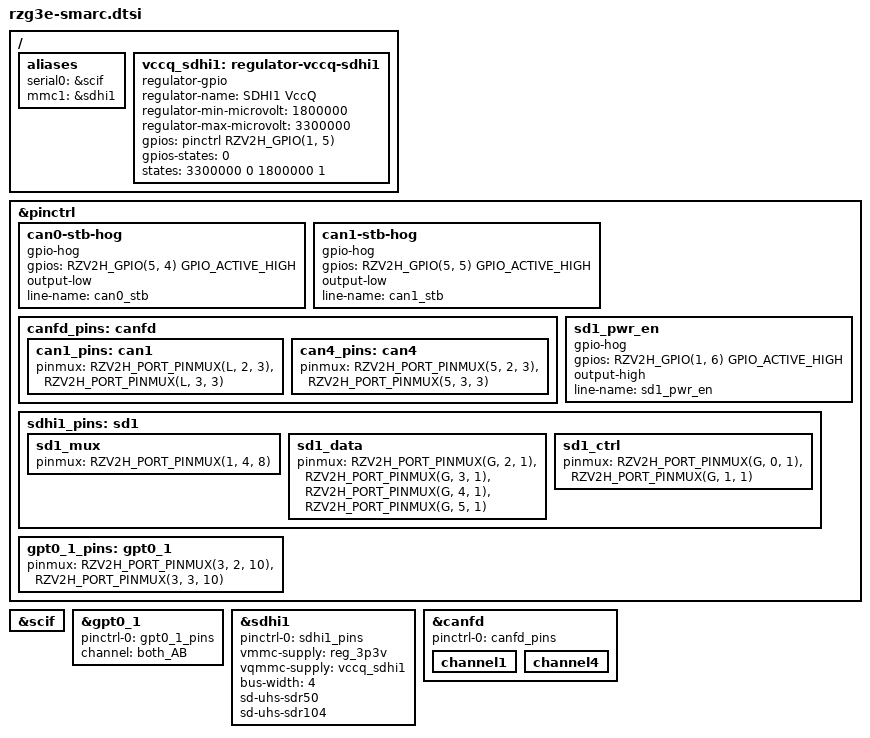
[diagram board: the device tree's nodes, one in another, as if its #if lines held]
// SPDX-License-Identifier: (GPL-2.0-only OR BSD-2-Clause)
/*
 * Device Tree Source for the RZ/G3E SMARC Carrier-II Board.
 *
 * Copyright (C) 2024 Renesas Electronics Corp.
 */

#include <dt-bindings/gpio/gpio.h>
#include <dt-bindings/pinctrl/rzv2h-pinctrl.h>
#include <dt-bindings/interrupt-controller/irqc-rzg2l.h>

/*
 * Please change the corresponding selection to below Macros:
 *
 * SW_SDIO_M2E:
 *	0 - Smarc SDIO signal is connected to uSD1
 *	1 - Smarc SDIO signal is connected to M.2 Key E connector
 *
 * SW_GPIO_CAN_PMOD states:
 *
 * Please change the corresponding selection to below Macros:
 *
 * SW_GPIO8_CAN0_STB:
 *	0 - Connect to GPIO8 PMOD (default)
 *	1 - Connect to CAN0 transceiver STB pin
 *
 * SW_GPIO9_CAN1_STB:
 *	0 - Connect to GPIO9 PMOD (default)
 *	1 - Connect to CAN1 transceiver STB pin
 */

/ {
	aliases {
		serial0 = &scif;
#if (!SW_SDIO_M2E)
		mmc1 = &sdhi1;
#endif
	};
#if (!SW_SDIO_M2E)
	vccq_sdhi1: regulator-vccq-sdhi1 {
		compatible = "regulator-gpio";

		regulator-name = "SDHI1 VccQ";
		regulator-min-microvolt = <1800000>;
		regulator-max-microvolt = <3300000>;

		gpios = <&pinctrl RZV2H_GPIO(1, 5) GPIO_ACTIVE_HIGH>;

		gpios-states = <0>;
		states = <3300000 0 1800000 1>;
	};
#endif
};

&pinctrl {
#if ((!SW_LCD_EN) && (SW_GPIO8_CAN0_STB))
	can0-stb-hog {
		gpio-hog;
		gpios = <RZV2H_GPIO(5, 4) GPIO_ACTIVE_HIGH>;
		output-low;
		line-name = "can0_stb";
	};
#endif

#if ((!SW_LCD_EN) && (SW_GPIO9_CAN1_STB))
	can1-stb-hog {
		gpio-hog;
		gpios = <RZV2H_GPIO(5, 5) GPIO_ACTIVE_HIGH>;
		output-low;
		line-name = "can1_stb";
	};
#endif

	canfd_pins: canfd {
#if (!SW_PDM_EN)
		can1_pins: can1 {
			pinmux = <RZV2H_PORT_PINMUX(L, 2, 3)>, /* RX */
				 <RZV2H_PORT_PINMUX(L, 3, 3)>; /* TX */
		};
#endif

#if (!SW_LCD_EN)
		can4_pins: can4 {
			pinmux = <RZV2H_PORT_PINMUX(5, 2, 3)>, /* RX */
				 <RZV2H_PORT_PINMUX(5, 3, 3)>; /* TX */
		};
#endif
	};

#if (!SW_SDIO_M2E)
	sd1_pwr_en {
		gpio-hog;
		gpios = <RZV2H_GPIO(1, 6) GPIO_ACTIVE_HIGH>;
		output-high;
		line-name = "sd1_pwr_en";
	};

	sdhi1_pins: sd1 {
		sd1_mux {
			pinmux = <RZV2H_PORT_PINMUX(1, 4, 8)>; /* QSD1_CD */
		};

		sd1_data {
			pinmux = <RZV2H_PORT_PINMUX(G, 2, 1)>, /* QSD1_DAT0 */
				 <RZV2H_PORT_PINMUX(G, 3, 1)>, /* QSD1_DAT1 */
				 <RZV2H_PORT_PINMUX(G, 4, 1)>, /* QSD1_DAT2 */
				 <RZV2H_PORT_PINMUX(G, 5, 1)>; /* QSD1_DAT3 */
		};

		sd1_ctrl {
			pinmux = <RZV2H_PORT_PINMUX(G, 0, 1)>, /* QSD2_CLK */
				 <RZV2H_PORT_PINMUX(G, 1, 1)>; /* QSD2_CMD */
		};
	};
#endif

	gpt0_1_pins: gpt0_1 {
			pinmux = <RZV2H_PORT_PINMUX(3, 2, 10)>,
				 <RZV2H_PORT_PINMUX(3, 3, 10)>;
	};
};

&scif {
	status = "okay";
};

&gpt0_1 {
        pinctrl-0 = <&gpt0_1_pins>;
        pinctrl-names = "default";
        channel = "both_AB";
        status = "okay";
};

&sdhi1 {
	pinctrl-0 = <&sdhi1_pins>;
	pinctrl-names = "default";
	vmmc-supply = <&reg_3p3v>;
	vqmmc-supply = <&vccq_sdhi1>;
	bus-width = <4>;
	sd-uhs-sdr50;
	sd-uhs-sdr104;

	status = "okay";
};
&canfd {
#if ((!SW_PDM_EN) || (!SW_LCD_EN))
	pinctrl-0 = <&canfd_pins>;
	pinctrl-names = "default";
	status = "okay";
#endif

#if (!SW_PDM_EN)
	channel1 {
		status = "okay";
	};
#endif

#if (!SW_LCD_EN)
	channel4 {
		status = "okay";
	};
#endif
};
